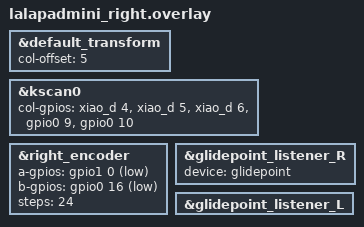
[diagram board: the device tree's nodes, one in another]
#include "lalapadmini.dtsi"

&default_transform {
    col-offset = <5>;
};

&kscan0 {
    col-gpios
        = <&xiao_d 4 GPIO_ACTIVE_HIGH>
        , <&xiao_d 5 GPIO_ACTIVE_HIGH>
        , <&xiao_d 6 GPIO_ACTIVE_HIGH>
        , <&gpio0  9 GPIO_ACTIVE_HIGH>
        , <&gpio0 10 GPIO_ACTIVE_HIGH>
        ;
};

&right_encoder {
    a-gpios = <&gpio1  0 (GPIO_ACTIVE_LOW | GPIO_PULL_UP)>;
    b-gpios = <&gpio0 16 (GPIO_ACTIVE_LOW | GPIO_PULL_UP)>;
    steps = <24>;
    status = "okay";
};

&glidepoint_listener_R {
    status = "okay";
    device = <&glidepoint>;
};
&glidepoint_listener_L {
    status = "okay";
};
